# tmr_reva_me10 register map
Registers are access not given, no defined reset value unless marked. A register's access mark holds for its fields unless they carry their own. Offsets are from the block's base; lines under a group give offsets from that group; [hi:lo] are bit positions; {n}, {i} and the like mark numbered series; 'fields as' and 'values as' point back to an identical list; <NAME> marks a mode.

## Memory map
0x40010000 TMR0 size 0x1000 — 32-bit reloadable timer that can be used for timing and event counting.

## Interrupts
5 TMR0 — TMR0 IRQ

## TMR0 — 32-bit reloadable timer that can be used for timing and event counting.
Base 0x40010000
0x00 CNT reset 0x1 — Count. This register stores the current timer count.
  [31:0] COUNT — Current count on the timer.
0x04 CMP reset 0xFFFF — Compare. This register stores the compare value, which is used to set the maximum count value to initiate a reload of the timer to 0x0001.
  [31:0] COMPARE — Timer compare value.
0x08 PWM — PWM. This register stores the value that is compared to the current timer count.
  [31:0] PWM — Timer PWM match value.
0x0C INTR write-1-clears — Clear Interrupt. Writing a value (0 or 1) to a bit in this register clears the associated interrupt.
  [0] IRQ — Clear Interrupt.
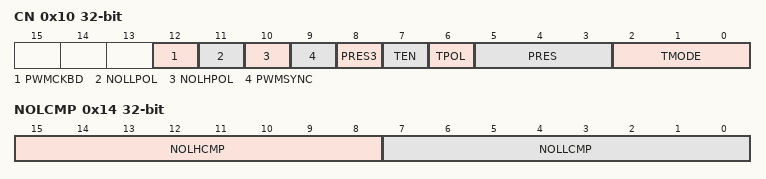
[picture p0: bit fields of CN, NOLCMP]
0x10 CN — Timer Control Register.
  [12] PWMCKBD — Timer PWM output 0A Mode Disable.
    1=dis (Disable.); 0=en (Enable.)
  [11] NOLLPOL — Timer PWM output 0A' polarity bit.
    0=Normal output polarity; 1=Inverted output polarity
  [10] NOLHPOL — Timer PWM output 0A polarity bit.
    0=Normal output polarity; 1=Inverted output polarity
  [9] PWMSYNC — Timer PWM Synchronization Mode Enable.
    0=dis (Disable.); 1=en (Enable.)
  [8] PRES3 — MSB of prescaler value.
    0=div1 (Divide by 1.); 0=div2 (Divide by 2.); 0=div4 (Divide by 4.); 0=div8 (Divide by 8.); 0=div16 (Divide by 16.); 0=div32 (Divide by 32.); 0=div64 (Divide by 64.); 0=div128 (Divide by 128.); 1=div256 (Divide by 256. Additionally, TMRn->cn.pres3 must be set.); 1=div512 (Divide by 512. Additionally, TMRn->cn.pres3 must be set.); 1=div1024 (Divide by 1024. Additionally, TMRn->cn.pres3 must be set.); 1=div2048 (Divide by 2048. Additionally, TMRn->cn.pres3 must be set.); 1=div4096 (Divide by 4096. Additionally, TMRn->cn.pres3 must be set.)
  [7] TEN — Timer Enable.
    0=dis (Disable.); 1=en (Enable.)
  [6] TPOL — Timer input/output polarity bit.
    0=Active High; 1=Active Low
  [5:3] PRES — Prescaler. Set the Timer's prescaler value. The prescaler divides the PCLK input to the timer and sets the Timer's Count Clock, F_CNT_CLK = PCLK (HZ) /prescaler. The Timer's prescaler setting is a 4-bit value with pres3:pres[2:0].
    0=div1 (Divide by 1.); 1=div2 (Divide by 2.); 2=div4 (Divide by 4.); 3=div8 (Divide by 8.); 4=div16 (Divide by 16.); 5=div32 (Divide by 32.); 6=div64 (Divide by 64.); 7=div128 (Divide by 128.); 0=div256 (Divide by 256. Additionally, TMRn->cn.pres3 must be set.); 2=div512 (Divide by 512. Additionally, TMRn->cn.pres3 must be set.); 3=div1024 (Divide by 1024. Additionally, TMRn->cn.pres3 must be set.); 4=div2048 (Divide by 2048. Additionally, TMRn->cn.pres3 must be set.); 5=div4096 (Divide by 4096. Additionally, TMRn->cn.pres3 must be set.)
  [2:0] TMODE — Timer Mode.
    0=One Shot Mode; 1=Continuous Mode; 2=Counter Mode; 3=pwm (PWM Mode.); 4=Capture Mode; 5=Compare Mode; 6=Gated Mode; 7=Capture/Compare Mode
0x14 NOLCMP — Timer Non-Overlapping Compare Register.
  [15:8] NOLHCMP — Non-overlapping High Compare. The 8-bit timer count value of non-overlapping time between falling edge of PWM output 0A' and next rising edge of PWM output 0A.
  [7:0] NOLLCMP — Non-overlapping Low Compare. The 8-bit timer count value of non-overlapping time between falling edge of PWM output 0A and next rising edge of PWM output 0A'.
